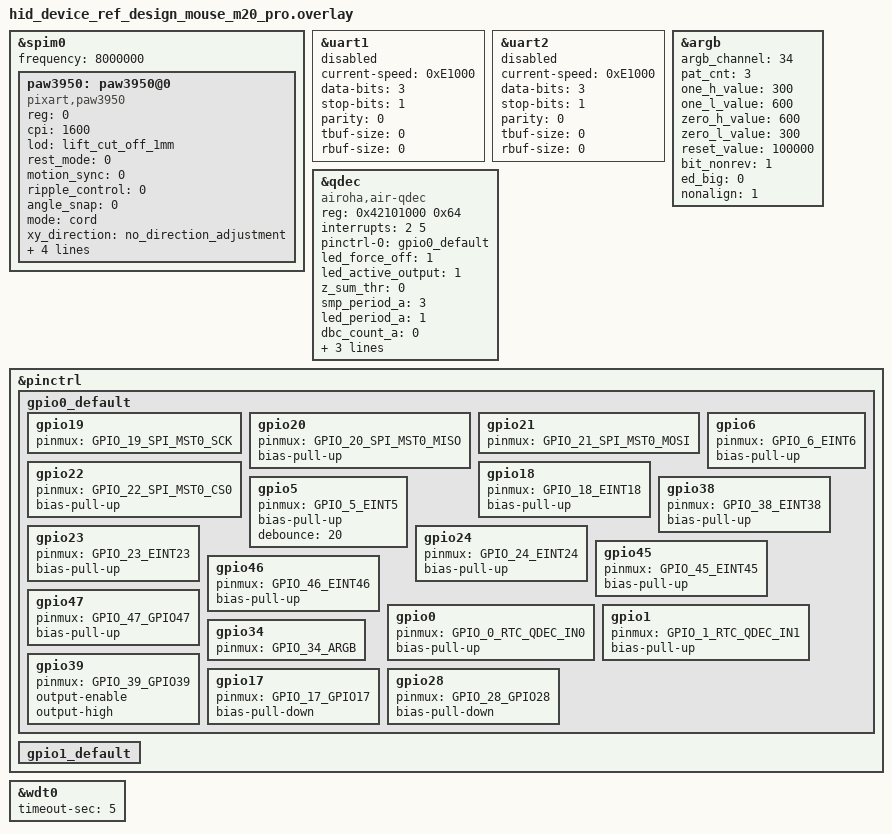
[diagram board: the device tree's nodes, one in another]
/* Copyright Statement:
 *
 * (C) 2024  Airoha Technology Corp. All rights reserved.
 *
 * This software/firmware and related documentation ("Airoha Software") are
 * protected under relevant copyright laws. The information contained herein
 * is confidential and proprietary to Airoha Technology Corp. ("Airoha") and/or its licensors.
 * Without the prior written permission of Airoha and/or its licensors,
 * any reproduction, modification, use or disclosure of Airoha Software,
 * and information contained herein, in whole or in part, shall be strictly prohibited.
 * You may only use, reproduce, modify, or distribute (as applicable) Airoha Software
 * if you have agreed to and been bound by the applicable license agreement with
 * Airoha ("License Agreement") and been granted explicit permission to do so within
 * the License Agreement ("Permitted User").  If you are not a Permitted User,
 * please cease any access or use of Airoha Software immediately.
 * BY OPENING THIS FILE, RECEIVER HEREBY UNEQUIVOCALLY ACKNOWLEDGES AND AGREES
 * THAT AIROHA SOFTWARE RECEIVED FROM AIROHA AND/OR ITS REPRESENTATIVES
 * ARE PROVIDED TO RECEIVER ON AN "AS-IS" BASIS ONLY. AIROHA EXPRESSLY DISCLAIMS ANY AND ALL
 * WARRANTIES, EXPRESS OR IMPLIED, INCLUDING BUT NOT LIMITED TO THE IMPLIED WARRANTIES OF
 * MERCHANTABILITY, FITNESS FOR A PARTICULAR PURPOSE OR NONINFRINGEMENT.
 * NEITHER DOES AIROHA PROVIDE ANY WARRANTY WHATSOEVER WITH RESPECT TO THE
 * SOFTWARE OF ANY THIRD PARTY WHICH MAY BE USED BY, INCORPORATED IN, OR
 * SUPPLIED WITH AIROHA SOFTWARE, AND RECEIVER AGREES TO LOOK ONLY TO SUCH
 * THIRD PARTY FOR ANY WARRANTY CLAIM RELATING THERETO. RECEIVER EXPRESSLY ACKNOWLEDGES
 * THAT IT IS RECEIVER'S SOLE RESPONSIBILITY TO OBTAIN FROM ANY THIRD PARTY ALL PROPER LICENSES
 * CONTAINED IN AIROHA SOFTWARE. AIROHA SHALL ALSO NOT BE RESPONSIBLE FOR ANY AIROHA
 * SOFTWARE RELEASES MADE TO RECEIVER'S SPECIFICATION OR TO CONFORM TO A PARTICULAR
 * STANDARD OR OPEN FORUM. RECEIVER'S SOLE AND EXCLUSIVE REMEDY AND AIROHA'S ENTIRE AND
 * CUMULATIVE LIABILITY WITH RESPECT TO AIROHA SOFTWARE RELEASED HEREUNDER WILL BE,
 * AT AIROHA'S OPTION, TO REVISE OR REPLACE AIROHA SOFTWARE AT ISSUE,
 * OR REFUND ANY SOFTWARE LICENSE FEES OR SERVICE CHARGE PAID BY RECEIVER TO
 * AIROHA FOR SUCH AIROHA SOFTWARE AT ISSUE.
 */


&spim0 {
	frequency = <8000000>;
	status = "okay";
	paw3950: paw3950@0{
		compatible = "pixart,paw3950";
		reg= <0>;
		cpi = <1600>;
		lod = "lift_cut_off_1mm";
		rest_mode = <0>;
		motion_sync = <0>;
		ripple_control = <0>;
		angle_snap = <0>;
		mode = "cord";
		xy_direction = "no_direction_adjustment";
		rest1_period_time = <1>;
		rest2_period_time = <20>;
		rest3_period_time = <160>;
		nreset_pin = <255>;
		status = "okay";
	};
};

&uart1 {
    status = "disabled";
    current-speed = < 0xE1000 >;
    data-bits = <3>;
    stop-bits = <1>;
    parity = <0>;
    tbuf-size = <0>;
    rbuf-size = <0>;
};
&uart2 {
    status = "disabled";
    current-speed = < 0xE1000 >;
    data-bits = <3>;
    stop-bits = <1>;
    parity = <0>;
    tbuf-size = <0>;
    rbuf-size = <0>;
};

&argb {
	status = "okay";
	argb_channel = <34>;
	pat_cnt = <3>;
	one_h_value   = <300>;    /* → HAL one_l = 300ns (1码低电平) */
	one_l_value   = <600>;    /* → HAL one_h = 900ns (1码高电平) */
	zero_h_value  = <600>;    /* → HAL zero_l = 900ns (0码低电平) */
	zero_l_value  = <300>;    /* → HAL zero_h = 300ns (0码高电平) */
	reset_value   = <100000>; /* ≥100us */
	bit_nonrev    = <1>;      /* 不反转bit位 */
	ed_big        = <0>;      /* 小端提取(软件补偿字节顺序) */
	nonalign      = <1>;      /* 1=启用nonalign模式(必须为1) */
};

&qdec {
	compatible = "airoha,air-qdec";
	reg = <0x42101000 0x64>;
	interrupts = <2 5>;
	pinctrl-0 = <&gpio0_default>;
	pinctrl-names = "default";
	status = "okay";
	led_force_off = <1>;
	led_active_output = <1>;
	z_sum_thr = <0>;
	smp_period_a = <3>;
	led_period_a = <1>;
	dbc_count_a = <0>;
	smp_period_b = <10>;
	led_period_b = <1>;
	dbc_count_b = <0>;
};

&pinctrl {

	gpio0_default: gpio0_default {
		/** SPI pins for motion sensor */
		gpio19{
			pinmux = <GPIO_19_SPI_MST0_SCK>;
		};
		gpio20{
			pinmux = <GPIO_20_SPI_MST0_MISO>;
			bias-pull-up;
		};
		gpio21{
			pinmux = <GPIO_21_SPI_MST0_MOSI>;
		};
		gpio22{
			pinmux = <GPIO_22_SPI_MST0_CS0>;
			bias-pull-up;
		};

		/** Interrupt pin of motion sensor */
		gpio18{
			pinmux = <GPIO_18_EINT18>;
			bias-pull-up;
		};

		/** Mouse L Key (LM7: GPIO6) */
		gpio6{
			pinmux = <GPIO_6_EINT6>;
			bias-pull-up;
		};

		/** Mouse R Key (LM7: GPIO5) */
		gpio5{
			pinmux = <GPIO_5_EINT5>;
			bias-pull-up;
			debounce = <20>;
		};

		/** Mouse M Key (LM7: GPIO38)*/
		gpio38{
			pinmux = <GPIO_38_EINT38>;
			bias-pull-up;
		};

		/** Mouse FW Key */
		gpio23{
			pinmux = <GPIO_23_EINT23>;
			bias-pull-up;
		};

		/** Mouse BW Key */
		gpio24{
			pinmux = <GPIO_24_EINT24>;
			bias-pull-up;
		};

		/** DPI Key -- LM7: GPIO29 used as ENC_POWER_EN (encoder power enable) */
		/* gpio29{
			pinmux = <GPIO_29_EINT29>;
			bias-pull-up;
		}; */
		
		/** Report Rate Change Key */
		gpio45{
			pinmux = <GPIO_45_EINT45>;
			bias-pull-up;
		};

		/** Slide Switch BT Mode */
		gpio46{
			pinmux = <GPIO_46_EINT46>;
			bias-pull-up;
		};

		/** Slide Switch Gaming Mode */
		gpio47{
			pinmux = <GPIO_47_EINT47>;
			bias-pull-up;
		};

		/** QDEC Input */
		gpio0{
			pinmux = <GPIO_0_RTC_QDEC_IN0>;
			bias-pull-up;
		};
		
		/** QDEC Input */
		gpio1{
			pinmux = <GPIO_1_RTC_QDEC_IN1>;
			bias-pull-up;
		};

		/** ARGB data pin */
		gpio34{
			pinmux = <GPIO_34_ARGB>;
		};

		/** LED_POWER_EN */
		gpio39{
			pinmux = <GPIO_39_GPIO39>;
			output-enable;
			output-high;
		};

		/** Mouse IR_ENABLE pin */
		gpio47{
			pinmux = <GPIO_47_GPIO47>;
			bias-pull-up;
		};
		/* HELL POWER EN */
		gpio17{
			pinmux = <GPIO_17_GPIO17>;
			bias-pull-down;
		};
		/* VDD HELL EN */
		gpio28{
			pinmux = <GPIO_28_GPIO28>;
			bias-pull-down;
		};
	};

	gpio1_default: gpio1_default {

	};
};

/* set WDT timeout to 5 second */
&wdt0 {
	timeout-sec = <5>;
};



